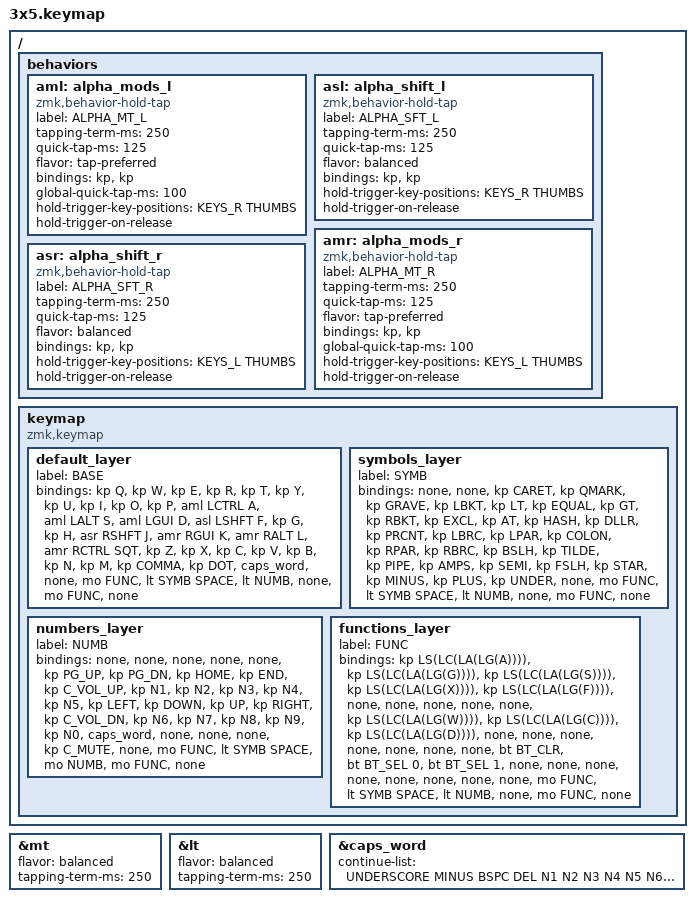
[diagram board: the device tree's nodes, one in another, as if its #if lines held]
#include <behaviors.dtsi>
#include <dt-bindings/zmk/keys.h>
#include <dt-bindings/zmk/bt.h>
#include <dt-bindings/zmk/outputs.h>
#ifdef EXTERNAL_POWER
#    include <dt-bindings/zmk/ext_power.h>
#endif

// Layer aliases
#define BASE 0
#define SYMB 1
#define NUMB 2
#define FUNC 3

// Desktop and tab navigation shortcuts
#define D_LT   LC(LG(LEFT))
#define D_RT   LC(LG(RIGHT))
#define TAB_RT LC(TAB)
#define TAB_LT LC(LS(TAB))

// Key position groups
#define KEYS_L 0 1 2 3 4 10 11 12 13 14 20 21 22 23 24
#define KEYS_R 5 6 7 8 9 15 16 17 18 19 25 26 27 28 29
#ifdef THREE_THUMBS
#    define THUMBS 30 31 32 33 34 35 
#else
#    define THUMBS 30 31 32 33
#endif

#include "combos.dtsi"

&mt {
    flavor = "balanced";
    tapping-term-ms = <250>;
};

&lt {
    flavor = "balanced";
    tapping-term-ms = <250>;
};

&caps_word {
    continue-list = <UNDERSCORE MINUS BSPC DEL N1 N2 N3 N4 N5 N6 N7 N8 N9 N0>;
};

/ {
    behaviors {
        aml: alpha_mods_l {
            compatible = "zmk,behavior-hold-tap";
            label = "ALPHA_MT_L";
            #binding-cells = <2>;
            tapping-term-ms = <250>;
            quick-tap-ms = <125>;
            flavor = "tap-preferred";
            bindings = <&kp>, <&kp>;
            global-quick-tap-ms = <100>;
			hold-trigger-key-positions = <KEYS_R THUMBS>;
			hold-trigger-on-release;
        };
        asl: alpha_shift_l {
            compatible = "zmk,behavior-hold-tap";
            label = "ALPHA_SFT_L";
            #binding-cells = <2>;
            tapping-term-ms = <250>;
            quick-tap-ms = <125>;
            flavor = "balanced";
            bindings = <&kp>, <&kp>;
			hold-trigger-key-positions = <KEYS_R THUMBS>;
			hold-trigger-on-release;
        };
        amr: alpha_mods_r {
            compatible = "zmk,behavior-hold-tap";
            label = "ALPHA_MT_R";
            #binding-cells = <2>;
            tapping-term-ms = <250>;
            quick-tap-ms = <125>;
            flavor = "tap-preferred";
            bindings = <&kp>, <&kp>;
            global-quick-tap-ms = <100>;
			hold-trigger-key-positions = <KEYS_L THUMBS>;
			hold-trigger-on-release;
        };
        asr: alpha_shift_r {
            compatible = "zmk,behavior-hold-tap";
            label = "ALPHA_SFT_R";
            #binding-cells = <2>;
            tapping-term-ms = <250>;
            quick-tap-ms = <125>;
            flavor = "balanced";
            bindings = <&kp>, <&kp>;
			hold-trigger-key-positions = <KEYS_L THUMBS>;
			hold-trigger-on-release;
        };
    };

    keymap {
        compatible = "zmk,keymap";

        default_layer {
            label = "BASE";
            bindings = <
// ╭─────────────┬─────────────┬─────────────┬─────────────┬─────────────╮   ╭─────────────┬─────────────┬─────────────┬─────────────┬─────────────╮
     &kp Q         &kp W         &kp E         &kp R         &kp T             &kp Y         &kp U         &kp I         &kp O         &kp P
// ├─────────────┼─────────────┼─────────────┼─────────────┼─────────────┤   ├─────────────┼─────────────┼─────────────┼─────────────┼─────────────┤
     &aml LCTRL A  &aml LALT S   &aml LGUI D   &asl LSHFT F  &kp G             &kp H         &asr RSHFT J  &amr RGUI K   &amr RALT L   &amr RCTRL SQT
// ├─────────────┼─────────────┼─────────────┼─────────────┼─────────────┤   ├─────────────┼─────────────┼─────────────┼─────────────┼─────────────┤
     &kp Z         &kp X         &kp C         &kp V         &kp B             &kp N         &kp M         &kp COMMA     &kp DOT       &caps_word
// ╰─────────────┴─────────────┴─────────────┼─────────────┼─────────────┤   ├─────────────┼─────────────┼─────────────┴─────────────┴─────────────╯
#ifdef THREE_THUMBS
                                    &none       &mo FUNC    &lt SYMB SPACE   &lt NUMB &none    &mo FUNC     &none          
#else
                                                &mo FUNC &lt SYMB SPACE      &lt NUMB &none    &mo FUNC
#endif
//                                           ╰─────────────┴─────────────╯   ╰─────────────┴─────────────╯
            >;
        };

        symbols_layer {
            label = "SYMB";
            bindings = <
// ╭─────────────┬─────────────┬─────────────┬─────────────┬─────────────╮   ╭─────────────┬─────────────┬─────────────┬─────────────┬─────────────╮
     &none         &none         &kp CARET     &kp QMARK     &kp GRAVE         &kp LBKT      &kp LT        &kp EQUAL     &kp GT        &kp RBKT
// ├─────────────┼─────────────┼─────────────┼─────────────┼─────────────┤   ├─────────────┼─────────────┼─────────────┼─────────────┼─────────────┤
     &kp EXCL      &kp AT        &kp HASH      &kp DLLR      &kp PRCNT         &kp LBRC      &kp LPAR      &kp COLON     &kp RPAR      &kp RBRC
// ├─────────────┼─────────────┼─────────────┼─────────────┼─────────────┤   ├─────────────┼─────────────┼─────────────┼─────────────┼─────────────┤
     &kp BSLH      &kp TILDE     &kp PIPE      &kp AMPS      &kp SEMI          &kp FSLH      &kp STAR      &kp MINUS     &kp PLUS      &kp UNDER
// ╰─────────────┴─────────────┴─────────────┼─────────────┼─────────────┤   ├─────────────┼─────────────┼─────────────┴─────────────┴─────────────╯
#ifdef THREE_THUMBS
                                    &none       &mo FUNC    &lt SYMB SPACE   &lt NUMB &none    &mo FUNC     &none
#else
                                                &mo FUNC    &lt SYMB SPACE      &mo NUMB       &mo FUNC
#endif
//                                           ╰─────────────┴─────────────╯   ╰─────────────┴─────────────╯
            >;
        };

        numbers_layer {
            label = "NUMB";
            bindings = <
// ╭─────────────┬─────────────┬─────────────┬─────────────┬─────────────╮   ╭─────────────┬─────────────┬─────────────┬─────────────┬─────────────╮
     &none         &none         &none         &none         &none             &kp PG_UP     &kp PG_DN     &kp HOME      &kp END       &kp C_VOL_UP
// ├─────────────┼─────────────┼─────────────┼─────────────┼─────────────┤   ├─────────────┼─────────────┼─────────────┼─────────────┼─────────────┤
     &kp N1        &kp N2        &kp N3        &kp N4        &kp N5            &kp LEFT      &kp DOWN      &kp UP        &kp RIGHT     &kp C_VOL_DN
// ├─────────────┼─────────────┼─────────────┼─────────────┼─────────────┤   ├─────────────┼─────────────┼─────────────┼─────────────┼─────────────┤
     &kp N6        &kp N7        &kp N8        &kp N9        &kp N0            &caps_word    &none         &none         &none         &kp C_MUTE
// ╰─────────────┴─────────────┴─────────────┼─────────────┼─────────────┤   ├─────────────┼─────────────┼─────────────┴─────────────┴─────────────╯
#ifdef THREE_THUMBS
                                    &none       &mo FUNC    &lt SYMB SPACE      &mo NUMB       &mo FUNC     &none
#else
                                                &mo FUNC &lt SYMB SPACE         &mo NUMB       &mo FUNC
#endif
//                                           ╰─────────────┴─────────────╯   ╰─────────────┴─────────────╯
            >;
        };

        functions_layer {
            label = "FUNC";
            bindings = <
// ╭─────────────┬─────────────┬─────────────┬─────────────┬─────────────╮   ╭─────────────┬─────────────┬─────────────┬─────────────┬─────────────╮
     &kp LS(LC(LA(LG(A)))) &kp LS(LC(LA(LG(G)))) &kp LS(LC(LA(LG(S)))) &kp LS(LC(LA(LG(X)))) &kp LS(LC(LA(LG(F)))) &none &none &none &none &none 
// ├─────────────┼─────────────┼─────────────┼─────────────┼─────────────┤   ├─────────────┼─────────────┼─────────────┼─────────────┼─────────────┤
     &kp LS(LC(LA(LG(W)))) &kp LS(LC(LA(LG(C)))) &kp LS(LC(LA(LG(D)))) &none &none &none     &none         &none         &none         &none 
// ├─────────────┼─────────────┼─────────────┼─────────────┼─────────────┤   ├─────────────┼─────────────┼─────────────┼─────────────┼─────────────┤
     &bt BT_CLR    &bt BT_SEL 0  &bt BT_SEL 1         &none         &none             &none         &none         &none         &none         &none
// ╰─────────────┴─────────────┴─────────────┼─────────────┼─────────────┤   ├─────────────┼─────────────┼─────────────┴─────────────┴─────────────╯
#ifdef THREE_THUMBS
                                    &none       &mo FUNC    &lt SYMB SPACE   &lt NUMB &none    &mo FUNC     &none
#else
                                                &mo FUNC &lt SYMB SPACE         &mo NUMB       &mo FUNC
#endif
//                                           ╰─────────────┴─────────────╯   ╰─────────────┴─────────────╯
            >;
        };
    };
};
